# Cortex_M52 register map
Vendor: Arm Ltd.; Series: ARMv8.1-M Mainline; File version: 1.0.0
CPU: other r0p0, little endian, MPU, FPU, double-precision FPU, DSP, 8 interrupt priority bits
Registers are 32-bit, read-write, reset 0x0 unless marked. A register's access mark holds for its fields unless they carry their own. Offsets are from the block's base; [hi:lo] are bit positions; {n}, {i} and the like mark numbered series.

## FPB — Flash Patch and Breakpoint unit (FPBv2): up to eight instruction address comparators for hardware breakpoints (halfword granular) and, if RMPSPT is set, literal comparators for remapping code-space loads.
Base 0xE0002000
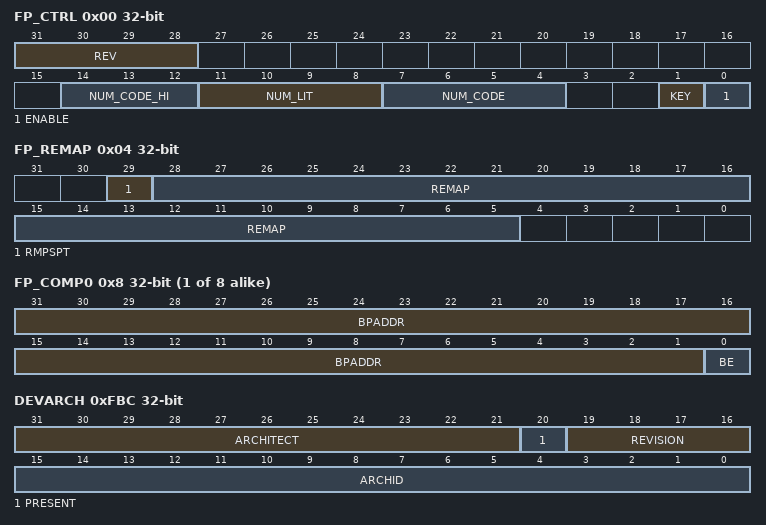
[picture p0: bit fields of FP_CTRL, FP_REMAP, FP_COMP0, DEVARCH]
0x00 FP_CTRL — Flash Patch Control Register: enable, and the number of comparators implemented. Writes must set KEY.
  [31:28] REV — Flash Patch and Breakpoint unit architecture revision: 0 = FPBv1 (ARMv7-M), 1 = FPBv2 (ARMv8-M).
  [14:12] NUM_CODE_HI — Number of instruction address comparators, bits [6:4].
  [11:8] NUM_LIT — Number of literal (data) address comparators; these are the last NUM_LIT comparators.
  [7:4] NUM_CODE — Number of instruction address comparators, bits [3:0] (with NUM_CODE_HI). Reads as zero if there are none.
  [1] KEY — Write 1 to enable writes to FP_CTRL; reads as zero. A write with KEY = 0 is ignored.
  [0] ENABLE — Flash Patch unit enable: 1 = breakpoint and remap comparators active. Reset value 0.
0x04 FP_REMAP — Flash Patch Remap Register: base address of the remap table when remapping is supported (RMPSPT); reserved otherwise.
  [29] RMPSPT — Remap supported: 1 = the FPB supports flash patch remapping, 0 = breakpoints only (typical on Cortex-M23/M33/M55/M85).
  [28:5] REMAP — Bits [28:5] of the remap base address (SRAM region).
{0x8+4i} FP_COMP{i} (i=0..7) — Flash Patch Comparator Register n: halfword-aligned instruction address to break on. Any address is allowed (not only the code region).
  [31:1] BPADDR — Bits [31:1] of the instruction address to match.
  [0] BE — Breakpoint enable.
0xFBC DEVARCH ro — Device Architecture Register: the architecture of the component (CoreSight ARCHID) and its architect.
  [31:21] ARCHITECT — JEP106 code of the architect (Arm: 0x23B).
  [20] PRESENT — 1 = DEVARCH is present and its contents are valid.
  [19:16] REVISION — Architecture revision.
  [15:0] ARCHID — Architecture ID, including the architecture part number [11:0] and revision [15:12].
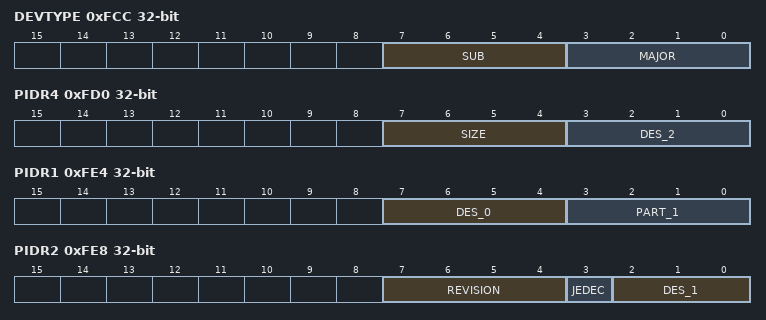
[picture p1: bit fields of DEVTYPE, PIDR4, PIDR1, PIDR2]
0xFCC DEVTYPE ro — Device Type Register: major and sub type of the CoreSight component.
  [7:4] SUB — Sub type within the major class.
  [3:0] MAJOR — Major type: 0 miscellaneous, 1 trace sink, 2 trace link, 3 trace source, 4 debug control, 5 debug logic, 6 PMU.
0xFD0 PIDR4 ro — Peripheral Identification Register 4: JEP106 continuation code and component size.
  [7:4] SIZE — Log2 of the number of 4 KB blocks the component occupies (0 = one block).
  [3:0] DES_2 — JEP106 continuation code of the designer (Arm: 0x4).
{0xFC0+4i} PIDR{i} ro (i=5..7) — Peripheral Identification Register {i} (reserved, reads as zero).
0xFE0 PIDR0 ro — Peripheral Identification Register 0: part number bits [7:0].
  [7:0] PART_0 — Part number bits [7:0].
0xFE4 PIDR1 ro — Peripheral Identification Register 1: part number bits [11:8] and designer bits [3:0].
  [7:4] DES_0 — JEP106 identity code bits [3:0] of the designer.
  [3:0] PART_1 — Part number bits [11:8].
0xFE8 PIDR2 ro — Peripheral Identification Register 2: designer bits [6:4], JEDEC flag and revision.
  [7:4] REVISION — Component major revision.
  [3] JEDEC — Always 1: the designer ID is a JEDEC JEP106 code.
  [2:0] DES_1 — JEP106 identity code bits [6:4] of the designer.
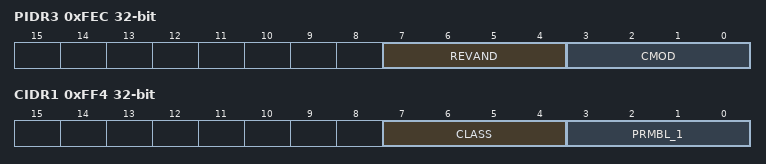
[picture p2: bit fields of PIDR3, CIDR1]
0xFEC PIDR3 ro — Peripheral Identification Register 3: customer modified and minor revision.
  [7:4] REVAND — Minor revision (metal fix) number.
  [3:0] CMOD — Customer Modified: 0 if the component has not been modified by the integrator.
0xFF0 CIDR0 ro — Component Identification Register 0: preamble byte 0 (0x0D).
  [7:0] PRMBL_0 — Preamble, reads as 0x0D.
0xFF4 CIDR1 ro — Component Identification Register 1: component class and preamble.
  [7:4] CLASS — Component class: 0x1 ROM table, 0x9 CoreSight component, 0xE generic IP, 0xF CoreLink/PrimeCell.
  [3:0] PRMBL_1 — Preamble, reads as 0x0.
0xFF8 CIDR2 ro — Component Identification Register 2: preamble byte 2 (0x05).
  [7:0] PRMBL_2 — Preamble, reads as 0x05.
0xFFC CIDR3 ro — Component Identification Register 3: preamble byte 3 (0xB1).
  [7:0] PRMBL_3 — Preamble, reads as 0xB1.
